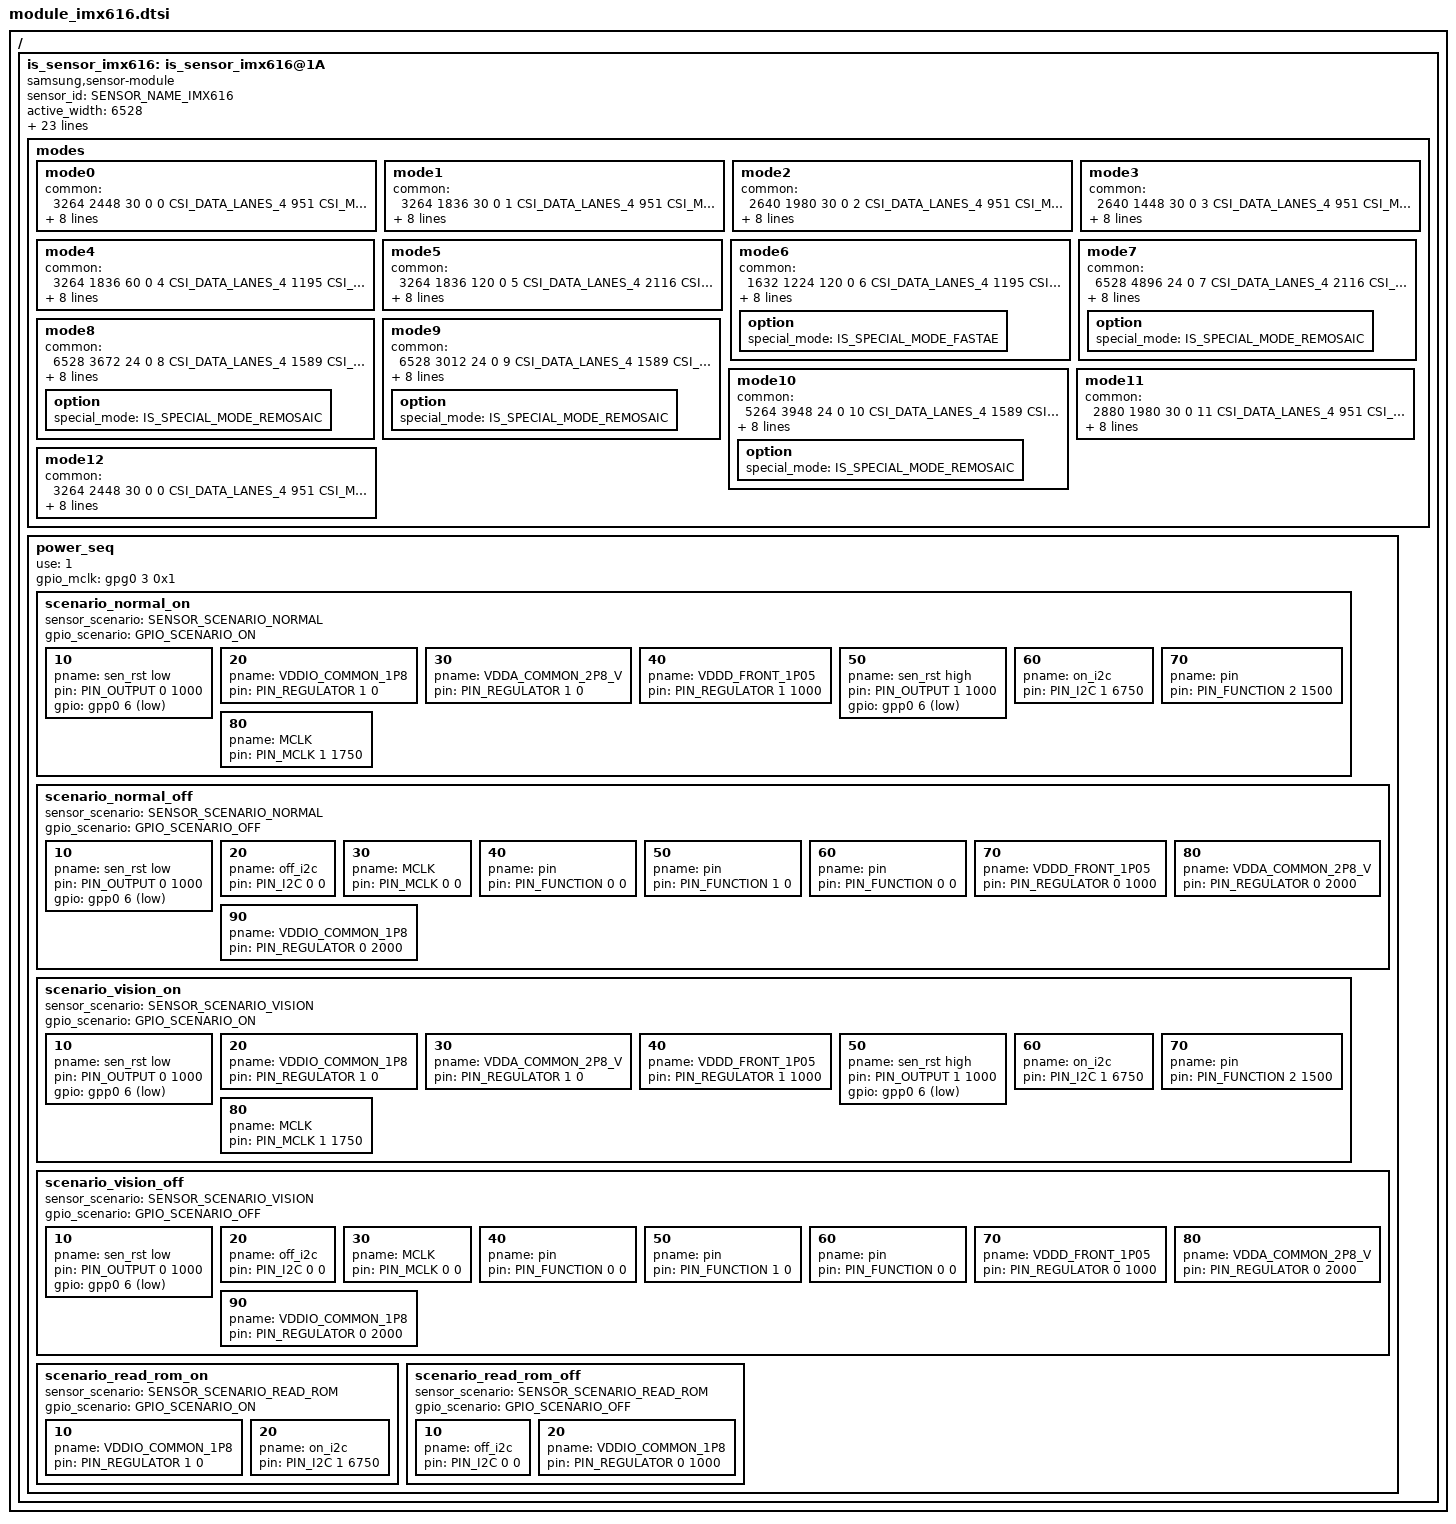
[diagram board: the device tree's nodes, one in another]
/*
 * SAMSUNG EXYNOSxxxx board camera device tree source
 *
 * Copyright (c) 2022 Samsung Electronics Co., Ltd.
 *		http://www.samsung.com
 *
 * This program is free software; you can redistribute it and/or modify
 * it under the terms of the GNU General Public License version 2 as
 * published by the Free Software Foundation.
 */

#include <dt-bindings/camera/exynos_is_dt.h>

/ {
	fragment@camera {
		target-path = "/";
		__overlay__ {
			is_sensor_imx616: is_sensor_imx616@1A {
				compatible = "samsung,sensor-module";

				/* common */
				sensor_id = <SENSOR_NAME_IMX616>;
				active_width = <6528>;
				active_height = <4896>;
				margin_left = <0>;
				margin_right = <0>;
				margin_top = <0>;
				margin_bottom = <0>;
				max_framerate = <120>;
				bitwidth = <10>;
				use_retention_mode = <SENSOR_RETENTION_INACTIVE>;
				sensor_maker = "SONY";
				sensor_name = "IMX616";
				setfile_name = "setfile_imx616.bin";

				status = "okay";
				/* board */
				pinctrl-names = "pin0", "pin1", "pin2", "release";
				pinctrl-0 = <>;
				pinctrl-1 = <&sensor_mclk2_out>;
				pinctrl-2 = <&sensor_mclk2_fn>;
				pinctrl-3 = <>;

				position = <1>; /* sensor position of camera dt */
				id = <1>; /* is_sensor id */
				mclk_ch = <2>;
				mclk_freq = <19200>;
				sensor_i2c_ch = <4>; /* SENSOR_CONTROL_I2C4 lock */

				/* vendor */
				rom_type = <2>; /* ROM_TYPE_EEPROM */
				rom_id = <1>;
				rom_cal_index = <0>;

				/*
				 * [Mode Information]
				 *
				 * Reference File : IMX616-AAJH5_SEC-DPHY_19.2M_RegisterSetting_ver1.00-21.01_b1_MP_230711
				 *
				 * -. Global Setting -
				 *
				 *
				 * [ 0 ] REG_A1 : 2x2Bin_4:3_30fps : Single Still Preview (4:3),  MIPI lane: 4, MIPI data rate(Mbps/lane): 665
				 * [ 1 ] REG_A2 : 2x2Bin_16:9_30fps  : Single Still Preview (16:9),  MIPI lane: 4, MIPI data rate(Mbps/lane): 526
				 *
				 */

				/* sensor modes */
				modes {
					/* common = <width, height, fps, settle, mode, lane, speed, interleave, lrte, pd_mode> */
					/* vcX = <map, hwformat, width, height, hwformat, type, width, height> */

					/* 0 : 2X2BIN_3264x2448_30FPS */
					mode0 {
						common = <3264 2448 30 0 0 CSI_DATA_LANES_4 951 CSI_MODE_DT_ONLY LRTE_DISABLE PD_NONE EX_NONE>;
						vc0 = </* in */ 0 HW_FORMAT_RAW10 DATA_IMG 3264 2448    /* out */ HW_FORMAT_RAW10 VC_NOTHING 3264 2448>;
						vc1 = </* in */ 1 HW_FORMAT_UNKNOWN DATA_NONE 0 0    /* out */ HW_FORMAT_UNKNOWN VC_NOTHING 0 0>;
						vc2 = </* in */ 2 HW_FORMAT_UNKNOWN DATA_NONE 0 0    /* out */ HW_FORMAT_UNKNOWN VC_NOTHING 0 0>;
						vc3 = </* in */ 3 HW_FORMAT_UNKNOWN DATA_NONE 0 0    /* out */ HW_FORMAT_UNKNOWN VC_NOTHING 0 0>;
					};
					/* 1 : 2X2BIN_3264x1836_30FPS */
					mode1 {
						common = <3264 1836 30 0 1 CSI_DATA_LANES_4 951 CSI_MODE_DT_ONLY LRTE_DISABLE PD_NONE EX_NONE>;
						vc0 = </* in */ 0 HW_FORMAT_RAW10 DATA_IMG 3264 1836    /* out */ HW_FORMAT_RAW10 VC_NOTHING 3264 1836>;
						vc1 = </* in */ 1 HW_FORMAT_UNKNOWN DATA_NONE 0 0    /* out */ HW_FORMAT_UNKNOWN VC_NOTHING 0 0>;
						vc2 = </* in */ 2 HW_FORMAT_UNKNOWN DATA_NONE 0 0    /* out */ HW_FORMAT_UNKNOWN VC_NOTHING 0 0>;
						vc3 = </* in */ 3 HW_FORMAT_UNKNOWN DATA_NONE 0 0    /* out */ HW_FORMAT_UNKNOWN VC_NOTHING 0 0>;
					};
					/* 2 : 2x2Bin_FHD_30fps */
					mode2 {
						common = <2640 1980 30 0 2 CSI_DATA_LANES_4 951 CSI_MODE_DT_ONLY LRTE_DISABLE PD_NONE EX_NONE>;
						vc0 = </* in */ 0 HW_FORMAT_RAW10 DATA_IMG 2640 1980   /* out */ HW_FORMAT_RAW10 VC_NOTHING 2640 1980>;
						vc1 = </* in */ 1 HW_FORMAT_UNKNOWN DATA_NONE 0 0    /* out */ HW_FORMAT_UNKNOWN VC_NOTHING 0 0>;
						vc2 = </* in */ 2 HW_FORMAT_UNKNOWN DATA_NONE 0 0    /* out */ HW_FORMAT_UNKNOWN VC_NOTHING 0 0>;
						vc3 = </* in */ 3 HW_FORMAT_UNKNOWN DATA_NONE 0 0    /* out */ HW_FORMAT_UNKNOWN VC_NOTHING 0 0>;
					};
					/* 3 : 2x2Bin_HD_30fps */
					mode3 {
						common = <2640 1448 30 0 3 CSI_DATA_LANES_4 951 CSI_MODE_DT_ONLY LRTE_DISABLE PD_NONE EX_NONE>;
						vc0 = </* in */ 0 HW_FORMAT_RAW10 DATA_IMG 2640 1448   /* out */ HW_FORMAT_RAW10 VC_NOTHING 2640 1448>;
						vc1 = </* in */ 1 HW_FORMAT_UNKNOWN DATA_NONE 0 0    /* out */ HW_FORMAT_UNKNOWN VC_NOTHING 0 0>;
						vc2 = </* in */ 2 HW_FORMAT_UNKNOWN DATA_NONE 0 0    /* out */ HW_FORMAT_UNKNOWN VC_NOTHING 0 0>;
						vc3 = </* in */ 3 HW_FORMAT_UNKNOWN DATA_NONE 0 0    /* out */ HW_FORMAT_UNKNOWN VC_NOTHING 0 0>;
					};
					/* 4 : 2x2Bin_16:9_60fps */
					mode4 {
						common = <3264 1836 60 0 4 CSI_DATA_LANES_4 1195 CSI_MODE_DT_ONLY LRTE_DISABLE PD_NONE EX_NONE>;
						vc0 = </* in */ 0 HW_FORMAT_RAW10 DATA_IMG 3264 1836    /* out */ HW_FORMAT_RAW10 VC_NOTHING 3264 1836>;
						vc1 = </* in */ 1 HW_FORMAT_UNKNOWN DATA_NONE 0 0    /* out */ HW_FORMAT_UNKNOWN VC_NOTHING 0 0>;
						vc2 = </* in */ 2 HW_FORMAT_UNKNOWN DATA_NONE 0 0    /* out */ HW_FORMAT_UNKNOWN VC_NOTHING 0 0>;
						vc3 = </* in */ 3 HW_FORMAT_UNKNOWN DATA_NONE 0 0    /* out */ HW_FORMAT_UNKNOWN VC_NOTHING 0 0>;
					};
					/* 5 : 2x2Bin_16:9_120fps */
					mode5 {
						common = <3264 1836 120 0 5 CSI_DATA_LANES_4 2116 CSI_MODE_DT_ONLY LRTE_DISABLE PD_NONE EX_NONE>;
						vc0 = </* in */ 0 HW_FORMAT_RAW10 DATA_IMG 3264 1836    /* out */ HW_FORMAT_RAW10 VC_NOTHING 3264 1836>;
						vc1 = </* in */ 1 HW_FORMAT_UNKNOWN DATA_NONE 0 0    /* out */ HW_FORMAT_UNKNOWN VC_NOTHING 0 0>;
						vc2 = </* in */ 2 HW_FORMAT_UNKNOWN DATA_NONE 0 0    /* out */ HW_FORMAT_UNKNOWN VC_NOTHING 0 0>;
						vc3 = </* in */ 3 HW_FORMAT_UNKNOWN DATA_NONE 0 0    /* out */ HW_FORMAT_UNKNOWN VC_NOTHING 0 0>;
					};
					/* 6 : H2V2Bin_4:3_120fps */
					mode6 {
						common = <1632 1224 120 0 6 CSI_DATA_LANES_4 1195 CSI_MODE_DT_ONLY LRTE_DISABLE PD_NONE EX_NONE>;
						vc0 = </* in */ 0 HW_FORMAT_RAW10 DATA_IMG 1632 1224    /* out */ HW_FORMAT_RAW10 VC_NOTHING 1632 1224>;
						vc1 = </* in */ 1 HW_FORMAT_UNKNOWN DATA_NONE 0 0    /* out */ HW_FORMAT_UNKNOWN VC_NOTHING 0 0>;
						vc2 = </* in */ 2 HW_FORMAT_UNKNOWN DATA_NONE 0 0    /* out */ HW_FORMAT_UNKNOWN VC_NOTHING 0 0>;
						vc3 = </* in */ 3 HW_FORMAT_UNKNOWN DATA_NONE 0 0    /* out */ HW_FORMAT_UNKNOWN VC_NOTHING 0 0>;
						option { special_mode = <IS_SPECIAL_MODE_FASTAE>; };
					};
					/* 7 : Full_4:3_24fps */
					mode7 {
						common = <6528 4896 24 0 7 CSI_DATA_LANES_4 2116 CSI_MODE_DT_ONLY LRTE_DISABLE PD_NONE EX_NONE>;
						vc0 = </* in */ 0 HW_FORMAT_RAW10 DATA_IMG 6528 4896   /* out */ HW_FORMAT_RAW10 VC_NOTHING 6528 4896>;
						vc1 = </* in */ 1 HW_FORMAT_UNKNOWN DATA_NONE 0 0    /* out */ HW_FORMAT_UNKNOWN VC_NOTHING 0 0>;
						vc2 = </* in */ 2 HW_FORMAT_UNKNOWN DATA_NONE 0 0    /* out */ HW_FORMAT_UNKNOWN VC_NOTHING 0 0>;
						vc3 = </* in */ 3 HW_FORMAT_UNKNOWN DATA_NONE 0 0    /* out */ HW_FORMAT_UNKNOWN VC_NOTHING 0 0>;
						option { special_mode = <IS_SPECIAL_MODE_REMOSAIC>; };
					};
					/* 8 : Full_16:9_24fps */
					mode8 {
						common = <6528 3672 24 0 8 CSI_DATA_LANES_4 1589 CSI_MODE_DT_ONLY LRTE_DISABLE PD_NONE EX_NONE>;
						vc0 = </* in */ 0 HW_FORMAT_RAW10 DATA_IMG 6528 3672   /* out */ HW_FORMAT_RAW10 VC_NOTHING 6528 3672>;
						vc1 = </* in */ 1 HW_FORMAT_UNKNOWN DATA_NONE 0 0    /* out */ HW_FORMAT_UNKNOWN VC_NOTHING 0 0>;
						vc2 = </* in */ 2 HW_FORMAT_UNKNOWN DATA_NONE 0 0    /* out */ HW_FORMAT_UNKNOWN VC_NOTHING 0 0>;
						vc3 = </* in */ 3 HW_FORMAT_UNKNOWN DATA_NONE 0 0    /* out */ HW_FORMAT_UNKNOWN VC_NOTHING 0 0>;
						option { special_mode = <IS_SPECIAL_MODE_REMOSAIC>; };
					};
					/* 9 : Full_Crop_2:1_24fps */
					mode9 {
						common = <6528 3012 24 0 9 CSI_DATA_LANES_4 1589 CSI_MODE_DT_ONLY LRTE_DISABLE PD_NONE EX_NONE>;
						vc0 = </* in */ 0 HW_FORMAT_RAW10 DATA_IMG 6528 3012   /* out */ HW_FORMAT_RAW10 VC_NOTHING 6528 3012>;
						vc1 = </* in */ 1 HW_FORMAT_UNKNOWN DATA_NONE 0 0    /* out */ HW_FORMAT_UNKNOWN VC_NOTHING 0 0>;
						vc2 = </* in */ 2 HW_FORMAT_UNKNOWN DATA_NONE 0 0    /* out */ HW_FORMAT_UNKNOWN VC_NOTHING 0 0>;
						vc3 = </* in */ 3 HW_FORMAT_UNKNOWN DATA_NONE 0 0    /* out */ HW_FORMAT_UNKNOWN VC_NOTHING 0 0>;
						option { special_mode = <IS_SPECIAL_MODE_REMOSAIC>; };
					};
					/* 10 : Full_Crop_4:3_24fps */
					mode10 {
						common = <5264 3948 24 0 10 CSI_DATA_LANES_4 1589 CSI_MODE_DT_ONLY LRTE_DISABLE PD_NONE EX_NONE>;
						vc0 = </* in */ 0 HW_FORMAT_RAW10 DATA_IMG 5264 3948   /* out */ HW_FORMAT_RAW10 VC_NOTHING 5264 3948>;
						vc1 = </* in */ 1 HW_FORMAT_UNKNOWN DATA_NONE 0 0    /* out */ HW_FORMAT_UNKNOWN VC_NOTHING 0 0>;
						vc2 = </* in */ 2 HW_FORMAT_UNKNOWN DATA_NONE 0 0    /* out */ HW_FORMAT_UNKNOWN VC_NOTHING 0 0>;
						vc3 = </* in */ 3 HW_FORMAT_UNKNOWN DATA_NONE 0 0    /* out */ HW_FORMAT_UNKNOWN VC_NOTHING 0 0>;
						option { special_mode = <IS_SPECIAL_MODE_REMOSAIC>; };
					};
					/* 11 : 2x2Bin_3:2_30fps */
					mode11 {
						common = <2880 1980 30 0 11 CSI_DATA_LANES_4 951 CSI_MODE_DT_ONLY LRTE_DISABLE PD_NONE EX_NONE>;
						vc0 = </* in */ 0 HW_FORMAT_RAW10 DATA_IMG 2880 1980    /* out */ HW_FORMAT_RAW10 VC_NOTHING 2880 1980>;
						vc1 = </* in */ 1 HW_FORMAT_UNKNOWN DATA_NONE 0 0    /* out */ HW_FORMAT_UNKNOWN VC_NOTHING 0 0>;
						vc2 = </* in */ 2 HW_FORMAT_UNKNOWN DATA_NONE 0 0    /* out */ HW_FORMAT_UNKNOWN VC_NOTHING 0 0>;
						vc3 = </* in */ 3 HW_FORMAT_UNKNOWN DATA_NONE 0 0    /* out */ HW_FORMAT_UNKNOWN VC_NOTHING 0 0>;
					};
					/* For SECURE CAMERA FD Scenario */
					mode12 {
						common = <3264 2448 30 0 0 CSI_DATA_LANES_4 951 CSI_MODE_DT_ONLY LRTE_DISABLE PD_NONE EX_PDAF_OFF>;
						vc0 = </* in */ 0 HW_FORMAT_RAW10 DATA_IMG 3264 2448    /* out */ HW_FORMAT_RAW10 VC_NOTHING 1632 1224>;
						vc1 = </* in */ 1 HW_FORMAT_UNKNOWN DATA_NONE 0 0    /* out */ HW_FORMAT_UNKNOWN VC_NOTHING 0 0>;
						vc2 = </* in */ 2 HW_FORMAT_UNKNOWN DATA_NONE 0 0    /* out */ HW_FORMAT_UNKNOWN VC_NOTHING 0 0>;
						vc3 = </* in */ 3 HW_FORMAT_UNKNOWN DATA_NONE 0 0    /* out */ HW_FORMAT_UNKNOWN VC_NOTHING 0 0>;
					};
				};

				power_seq {
					use = <1>;
					gpio_mclk = <&gpg0 3 0x1>;

					scenario_normal_on {
						sensor_scenario = <SENSOR_SCENARIO_NORMAL>;
						gpio_scenario = <GPIO_SCENARIO_ON>;

						/* A start node number should be over the 10 for reserved number 0~9. */
						/* pname = "name"; pin = <act value delay voltage>; gpio = <gpx# # 0x1>; */
						10 { pname = "sen_rst low"; pin = <PIN_OUTPUT 0 1000>; gpio = <&gpp0 6 0x1>; };
						20 { pname = "VDDIO_COMMON_1P8"; pin = <PIN_REGULATOR 1 0>; };
						30 { pname = "VDDA_COMMON_2P8_V"; pin = <PIN_REGULATOR 1 0>; };
						40 { pname = "VDDD_FRONT_1P05"; pin = <PIN_REGULATOR 1 1000>; };
						50 { pname = "sen_rst high"; pin = <PIN_OUTPUT 1 1000>; gpio = <&gpp0 6 0x1>; };
						60 { pname = "on_i2c"; pin = <PIN_I2C 1 6750>; };
						70 { pname = "pin"; pin = <PIN_FUNCTION 2 1500>; };
						80 { pname = "MCLK"; pin = <PIN_MCLK 1 1750>; };
					};

					scenario_normal_off {
						sensor_scenario = <SENSOR_SCENARIO_NORMAL>;
						gpio_scenario = <GPIO_SCENARIO_OFF>;

						/* A start node number should be over the 10 for reserved number 0~9. */
						/* pname = "name"; pin = <act value delay voltage>; gpio = <gpx# # 0x1>; */
						10 { pname = "sen_rst low"; pin = <PIN_OUTPUT 0 1000>; gpio = <&gpp0 6 0x1>; };
						20 { pname = "off_i2c"; pin = <PIN_I2C 0 0>; };
						30 { pname = "MCLK"; pin = <PIN_MCLK 0 0>; };
						40 { pname = "pin"; pin = <PIN_FUNCTION 0 0>; };
						50 { pname = "pin"; pin = <PIN_FUNCTION 1 0>; };
						60 { pname = "pin"; pin = <PIN_FUNCTION 0 0>; };
						70 { pname = "VDDD_FRONT_1P05"; pin = <PIN_REGULATOR 0 1000>; };
						80 { pname = "VDDA_COMMON_2P8_V"; pin = <PIN_REGULATOR 0 2000>; };
						90 { pname = "VDDIO_COMMON_1P8"; pin = <PIN_REGULATOR 0 2000>; };
					};

					scenario_vision_on {
						sensor_scenario = <SENSOR_SCENARIO_VISION>;
						gpio_scenario = <GPIO_SCENARIO_ON>;

						/* A start node number should be over the 10 for reserved number 0~9. */
						/* pname = "name"; pin = <act value delay voltage>; gpio = <gpx# # 0x1>; */
						10 { pname = "sen_rst low"; pin = <PIN_OUTPUT 0 1000>; gpio = <&gpp0 6 0x1>; };
						20 { pname = "VDDIO_COMMON_1P8"; pin = <PIN_REGULATOR 1 0>; };
						30 { pname = "VDDA_COMMON_2P8_V"; pin = <PIN_REGULATOR 1 0>; };
						40 { pname = "VDDD_FRONT_1P05"; pin = <PIN_REGULATOR 1 1000>; };
						50 { pname = "sen_rst high"; pin = <PIN_OUTPUT 1 1000>; gpio = <&gpp0 6 0x1>; };
						60 { pname = "on_i2c"; pin = <PIN_I2C 1 6750>; };
						70 { pname = "pin"; pin = <PIN_FUNCTION 2 1500>; };
						80 { pname = "MCLK"; pin = <PIN_MCLK 1 1750>; };
					};

					scenario_vision_off {
						sensor_scenario = <SENSOR_SCENARIO_VISION>;
						gpio_scenario = <GPIO_SCENARIO_OFF>;

						/* A start node number should be over the 10 for reserved number 0~9. */
						/* pname = "name"; pin = <act value delay voltage>; gpio = <gpx# # 0x1>; */
						10 { pname = "sen_rst low"; pin = <PIN_OUTPUT 0 1000>; gpio = <&gpp0 6 0x1>; };
						20 { pname = "off_i2c"; pin = <PIN_I2C 0 0>; };
						30 { pname = "MCLK"; pin = <PIN_MCLK 0 0>; };
						40 { pname = "pin"; pin = <PIN_FUNCTION 0 0>; };
						50 { pname = "pin"; pin = <PIN_FUNCTION 1 0>; };
						60 { pname = "pin"; pin = <PIN_FUNCTION 0 0>; };
						70 { pname = "VDDD_FRONT_1P05"; pin = <PIN_REGULATOR 0 1000>; };
						80 { pname = "VDDA_COMMON_2P8_V"; pin = <PIN_REGULATOR 0 2000>; };
						90 { pname = "VDDIO_COMMON_1P8"; pin = <PIN_REGULATOR 0 2000>; };
					};

					scenario_read_rom_on {
						sensor_scenario = <SENSOR_SCENARIO_READ_ROM>;
						gpio_scenario = <GPIO_SCENARIO_ON>;

						/* A start node number should be over the 10 for reserved number 0~9. */
						/* pname = "name"; pin = <act value delay voltage>; gpio = <gpx# # 0x1>; */
						10 { pname = "VDDIO_COMMON_1P8"; pin = <PIN_REGULATOR 1 0>; };
						20 { pname = "on_i2c"; pin = <PIN_I2C 1 6750>; };
					};

					scenario_read_rom_off {
						sensor_scenario = <SENSOR_SCENARIO_READ_ROM>;
						gpio_scenario = <GPIO_SCENARIO_OFF>;

						/* A start node number should be over the 10 for reserved number 0~9. */
						/* pname = "name"; pin = <act value delay voltage>; gpio = <gpx# # 0x1>; */
						10 { pname = "off_i2c"; pin = <PIN_I2C 0 0>; };
						20 { pname = "VDDIO_COMMON_1P8"; pin = <PIN_REGULATOR 0 1000>; };
					};
				};
			};
		}; /* end of __overlay__ */
	}; /* end of fragment */
}; /* end of root */
